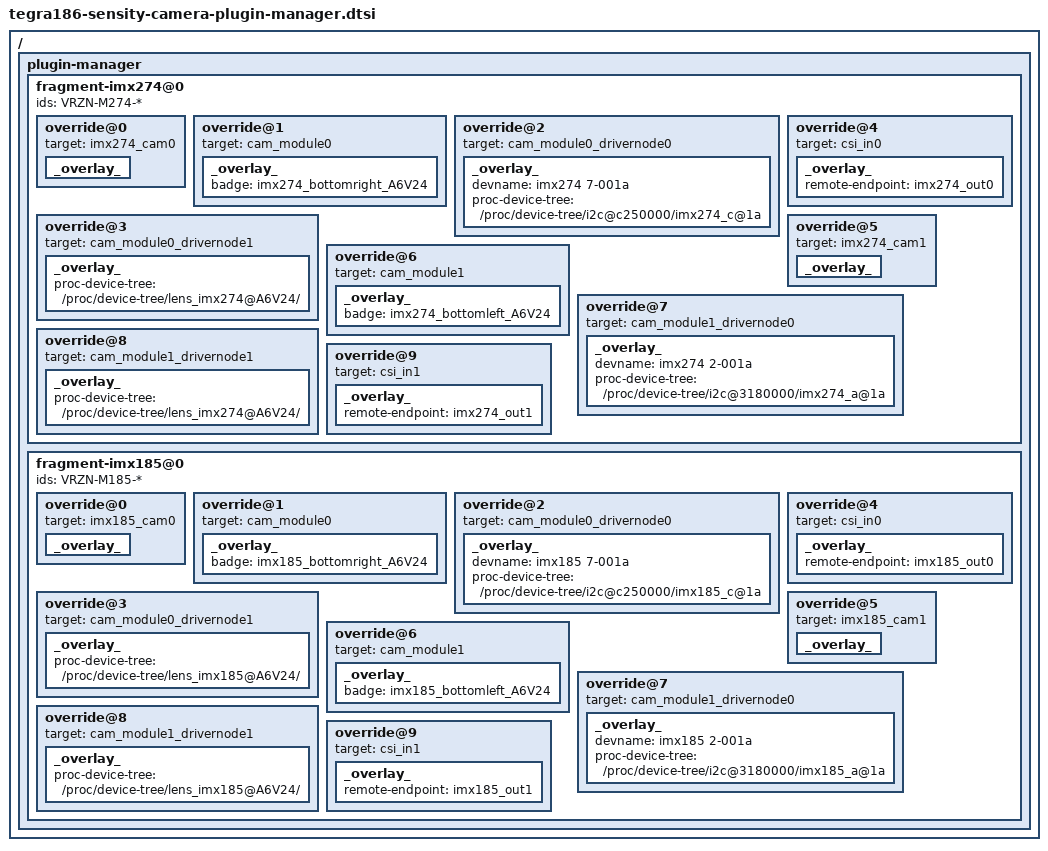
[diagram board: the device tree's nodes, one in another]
/*
 * Copyright (c) 2018 Verizon Communications, Inc.
 *
 * This program is free software; you can redistribute it and/or modify
 * it under the terms of the GNU General Public License as published by
 * the Free Software Foundation; either version 2 of the License, or
 * (at your option) any later version.
 *
 * This program is distributed in the hope that it will be useful, but WITHOUT
 * ANY WARRANTY; without even the implied warranty of MERCHANTABILITY or
 * FITNESS FOR A PARTICULAR PURPOSE.  See the GNU General Public License for
 * more details.
 *
 * You should have received a copy of the GNU General Public License
 * along with this program.  If not, see <http://www.gnu.org/licenses/>.
 */

/ {
	plugin-manager {
		fragment-imx274@0 {
			ids = "VRZN-M274-*";
			override@0 {
				target = <&imx274_cam0>;
				_overlay_ {
					status = "okay";
				};
			};
			override@1 {
				target = <&cam_module0>;
				_overlay_ {
					status = "okay";
					badge = "imx274_bottomright_A6V24";
				};
			};
			override@2 {
				target = <&cam_module0_drivernode0>;
				_overlay_ {
					status = "okay";
					devname = "imx274 7-001a";
					proc-device-tree = "/proc/device-tree/i2c@c250000/imx274_c@1a";
				};
			};
			override@3 {
				target = <&cam_module0_drivernode1>;
				_overlay_ {
					status = "okay";
					proc-device-tree = "/proc/device-tree/lens_imx274@A6V24/";
				};
			};
			override@4 {
				target = <&csi_in0>;
				_overlay_ {
					status = "okay";
					remote-endpoint = <&imx274_out0>;
				};
			};
			override@5 {
				target = <&imx274_cam1>;
				_overlay_ {
					status = "okay";
				};
			};
			override@6 {
				target = <&cam_module1>;
				_overlay_ {
					status = "okay";
					badge = "imx274_bottomleft_A6V24";
				};
			};
			override@7 {
				target = <&cam_module1_drivernode0>;
				_overlay_ {
					status = "okay";
					devname = "imx274 2-001a";
					proc-device-tree = "/proc/device-tree/i2c@3180000/imx274_a@1a";
				};
			};
			override@8 {
				target = <&cam_module1_drivernode1>;
				_overlay_ {
					status = "okay";
					proc-device-tree = "/proc/device-tree/lens_imx274@A6V24/";
				};
			};
			override@9 {
				target = <&csi_in1>;
				_overlay_ {
					status = "okay";
					remote-endpoint = <&imx274_out1>;
				};
			};
		};

		fragment-imx185@0 {
			ids = "VRZN-M185-*";
			override@0 {
				target = <&imx185_cam0>;
				_overlay_ {
					status = "okay";
				};
			};
			override@1 {
				target = <&cam_module0>;
				_overlay_ {
					status = "okay";
					badge = "imx185_bottomright_A6V24";
				};
			};
			override@2 {
				target = <&cam_module0_drivernode0>;
				_overlay_ {
					status = "okay";
					devname = "imx185 7-001a";
					proc-device-tree = "/proc/device-tree/i2c@c250000/imx185_c@1a";
				};
			};
			override@3 {
				target = <&cam_module0_drivernode1>;
				_overlay_ {
					status = "okay";
					proc-device-tree = "/proc/device-tree/lens_imx185@A6V24/";
				};
			};
			override@4 {
				target = <&csi_in0>;
				_overlay_ {
					status = "okay";
					remote-endpoint = <&imx185_out0>;
				};
			};
			override@5 {
				target = <&imx185_cam1>;
				_overlay_ {
					status = "okay";
				};
			};
			override@6 {
				target = <&cam_module1>;
				_overlay_ {
					status = "okay";
					badge = "imx185_bottomleft_A6V24";
				};
			};
			override@7 {
				target = <&cam_module1_drivernode0>;
				_overlay_ {
					status = "okay";
					devname = "imx185 2-001a";
					proc-device-tree = "/proc/device-tree/i2c@3180000/imx185_a@1a";
				};
			};
			override@8 {
				target = <&cam_module1_drivernode1>;
				_overlay_ {
					status = "okay";
					proc-device-tree = "/proc/device-tree/lens_imx185@A6V24/";
				};
			};
			override@9 {
				target = <&csi_in1>;
				_overlay_ {
					status = "okay";
					remote-endpoint = <&imx185_out1>;
				};
			};
		};
	};
};
